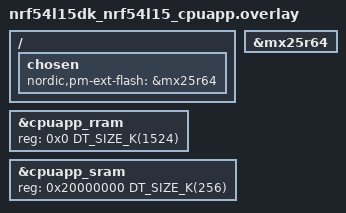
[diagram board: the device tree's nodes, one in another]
/*
 * Copyright (c) 2025 Nordic Semiconductor ASA
 *
 * SPDX-License-Identifier: LicenseRef-Nordic-5-Clause
 */

/ {
	chosen {
		nordic,pm-ext-flash = &mx25r64;
	};
};

&cpuapp_rram {
	reg = <0x0 DT_SIZE_K(1524)>;
};

&cpuapp_sram {
	reg = <0x20000000 DT_SIZE_K(256)>;
	ranges = <0x0 0x20000000 0x40000>;
};

&mx25r64 {
	status = "okay";
};
